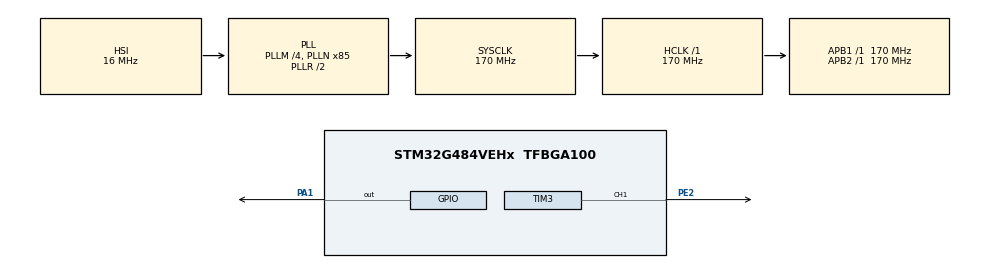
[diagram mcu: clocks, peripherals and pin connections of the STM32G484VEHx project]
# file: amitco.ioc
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Mcu.Family=STM32G4
Mcu.Name=STM32G484VEHx
Mcu.Package=TFBGA100
NVIC.PriorityGroup=NVIC_PRIORITYGROUP_4
PA1.Signal=GPIO_Output
PE2.Signal=S_TIM3_CH1
ProjectManager.HeapSize=0x200
ProjectManager.StackSize=0x400
ProjectManager.TargetToolchain=STM32CubeIDE
RCC.ADC12Freq_Value=170000000
RCC.ADC345Freq_Value=170000000
RCC.AHBFreq_Value=170000000
RCC.APB1Freq_Value=170000000
RCC.APB1TimFreq_Value=170000000
RCC.APB2Freq_Value=170000000
RCC.APB2TimFreq_Value=170000000
RCC.CortexFreq_Value=170000000
RCC.EXTERNAL_CLOCK_VALUE=12288000
RCC.HCLKFreq_Value=170000000
RCC.HSE_VALUE=8000000
RCC.HSI48_VALUE=48000000
RCC.HSI_VALUE=16000000
RCC.LSE_VALUE=32768
RCC.PLLM=RCC_PLLM_DIV4
RCC.PLLN=85
RCC.SYSCLKFreq_VALUE=170000000
RCC.SYSCLKSource=RCC_SYSCLKSOURCE_PLLCLK
RCC.USBFreq_Value=170000000
RCC.VCOOutputFreq_Value=340000000
SH.S_TIM3_CH1.0=TIM3_CH1,Output Compare1 CH1
TIM2.PeriodNoDither=9999
TIM2.Prescaler=169
TIM3.Channel-Output\ Compare1\ CH1=TIM_CHANNEL_1
TIM3.OCMode_1=TIM_OCMODE_TOGGLE
TIM3.PeriodNoDither=9999
TIM3.Prescaler=169
TIM3.PulseNoDither_1=5000
TIM3.TIM_MasterOutputTrigger=TIM_TRGO_OC1REF
VP_SYS_VS_DBSignals.Mode=DisableDeadBatterySignals
VP_TIM2_VS_ClockSourceINT.Mode=Internal
VP_TIM2_VS_ClockSourceITR.Mode=TriggerSource_ITR2
VP_TIM2_VS_ControllerModeReset.Mode=Reset Mode
VP_TIM3_VS_ClockSourceINT.Mode=Internal
board=custom

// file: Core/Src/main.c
/* USER CODE BEGIN Header */
/**
  ******************************************************************************
  * @file           : main.c
  * @brief          : Main program body
  ******************************************************************************
  * @attention
  *
  * Copyright (c) 2025 STMicroelectronics.
  * All rights reserved.
  *
  * This software is licensed under terms that can be found in the LICENSE file
  * in the root directory of this software component.
  * If no LICENSE file comes with this software, it is provided AS-IS.
  *
  ******************************************************************************
  */
/* USER CODE END Header */
#include "main.h"

TIM_HandleTypeDef htim2;
TIM_HandleTypeDef htim3;

/* USER CODE BEGIN PV */
volatile uint32_t tim2_cnt = 0;
volatile uint32_t tim3_cnt = 0;
/* USER CODE END PV */

void SystemClock_Config(void);
static void MX_GPIO_Init(void);
static void MX_TIM2_Init(void);
static void MX_TIM3_Init(void);

int main(void)
{

  /* MCU Configuration--------------------------------------------------------*/

  /* Reset of all peripherals, Initializes the Flash interface and the Systick. */
  HAL_Init();

  /* Configure the system clock */
  SystemClock_Config();

  /* Initialize all configured peripherals */
  MX_GPIO_Init();
  MX_TIM2_Init();
  MX_TIM3_Init();
  /* USER CODE BEGIN 2 */
  HAL_TIM_Base_Start(&htim2);
  HAL_TIM_Base_Start(&htim3);
  HAL_TIM_OC_Start(&htim3, TIM_CHANNEL_1);
  /* USER CODE END 2 */

  /* Infinite loop */
  while (1)
  {

    /* USER CODE BEGIN 3 */
  tim3_cnt = __HAL_TIM_GET_COUNTER(&htim3);
  tim2_cnt = __HAL_TIM_GET_COUNTER(&htim2);
  HAL_Delay(50);

  }
  /* USER CODE END 3 */
}

void SystemClock_Config(void)
{
  RCC_OscInitTypeDef RCC_OscInitStruct = {0};
  RCC_ClkInitTypeDef RCC_ClkInitStruct = {0};

  /** Configure the main internal regulator output voltage
  */
  HAL_PWREx_ControlVoltageScaling(PWR_REGULATOR_VOLTAGE_SCALE1_BOOST);

  /** Initializes the RCC Oscillators according to the specified parameters
  * in the RCC_OscInitTypeDef structure.
  */
  RCC_OscInitStruct.OscillatorType = RCC_OSCILLATORTYPE_HSI;
  RCC_OscInitStruct.HSIState = RCC_HSI_ON;
  RCC_OscInitStruct.HSICalibrationValue = RCC_HSICALIBRATION_DEFAULT;
  RCC_OscInitStruct.PLL.PLLState = RCC_PLL_ON;
  RCC_OscInitStruct.PLL.PLLSource = RCC_PLLSOURCE_HSI;
  RCC_OscInitStruct.PLL.PLLM = RCC_PLLM_DIV4;
  RCC_OscInitStruct.PLL.PLLN = 85;
  RCC_OscInitStruct.PLL.PLLP = RCC_PLLP_DIV2;
  RCC_OscInitStruct.PLL.PLLQ = RCC_PLLQ_DIV2;
  RCC_OscInitStruct.PLL.PLLR = RCC_PLLR_DIV2;
  if (HAL_RCC_OscConfig(&RCC_OscInitStruct) != HAL_OK)
  {
    Error_Handler();
  }

  /** Initializes the CPU, AHB and APB buses clocks
  */
  RCC_ClkInitStruct.ClockType = RCC_CLOCKTYPE_HCLK|RCC_CLOCKTYPE_SYSCLK
                              |RCC_CLOCKTYPE_PCLK1|RCC_CLOCKTYPE_PCLK2;
  RCC_ClkInitStruct.SYSCLKSource = RCC_SYSCLKSOURCE_PLLCLK;
  RCC_ClkInitStruct.AHBCLKDivider = RCC_SYSCLK_DIV1;
  RCC_ClkInitStruct.APB1CLKDivider = RCC_HCLK_DIV1;
  RCC_ClkInitStruct.APB2CLKDivider = RCC_HCLK_DIV1;

  if (HAL_RCC_ClockConfig(&RCC_ClkInitStruct, FLASH_LATENCY_4) != HAL_OK)
  {
    Error_Handler();
  }
}

static void MX_TIM2_Init(void)
{

  TIM_ClockConfigTypeDef sClockSourceConfig = {0};
  TIM_SlaveConfigTypeDef sSlaveConfig = {0};
  TIM_MasterConfigTypeDef sMasterConfig = {0};

  htim2.Instance = TIM2;
  htim2.Init.Prescaler = 169;
  htim2.Init.CounterMode = TIM_COUNTERMODE_UP;
  htim2.Init.Period = 9999;
  htim2.Init.ClockDivision = TIM_CLOCKDIVISION_DIV1;
  htim2.Init.AutoReloadPreload = TIM_AUTORELOAD_PRELOAD_DISABLE;
  if (HAL_TIM_Base_Init(&htim2) != HAL_OK)
  {
    Error_Handler();
  }
  sClockSourceConfig.ClockSource = TIM_CLOCKSOURCE_INTERNAL;
  if (HAL_TIM_ConfigClockSource(&htim2, &sClockSourceConfig) != HAL_OK)
  {
    Error_Handler();
  }
  sSlaveConfig.SlaveMode = TIM_SLAVEMODE_RESET;
  sSlaveConfig.InputTrigger = TIM_TS_ITR2;
  if (HAL_TIM_SlaveConfigSynchro(&htim2, &sSlaveConfig) != HAL_OK)
  {
    Error_Handler();
  }
  sMasterConfig.MasterOutputTrigger = TIM_TRGO_RESET;
  sMasterConfig.MasterSlaveMode = TIM_MASTERSLAVEMODE_DISABLE;
  if (HAL_TIMEx_MasterConfigSynchronization(&htim2, &sMasterConfig) != HAL_OK)
  {
    Error_Handler();
  }

}

static void MX_TIM3_Init(void)
{

  TIM_ClockConfigTypeDef sClockSourceConfig = {0};
  TIM_MasterConfigTypeDef sMasterConfig = {0};
  TIM_OC_InitTypeDef sConfigOC = {0};

  htim3.Instance = TIM3;
  htim3.Init.Prescaler = 169;
  htim3.Init.CounterMode = TIM_COUNTERMODE_UP;
  htim3.Init.Period = 9999;
  htim3.Init.ClockDivision = TIM_CLOCKDIVISION_DIV1;
  htim3.Init.AutoReloadPreload = TIM_AUTORELOAD_PRELOAD_DISABLE;
  if (HAL_TIM_Base_Init(&htim3) != HAL_OK)
  {
    Error_Handler();
  }
  sClockSourceConfig.ClockSource = TIM_CLOCKSOURCE_INTERNAL;
  if (HAL_TIM_ConfigClockSource(&htim3, &sClockSourceConfig) != HAL_OK)
  {
    Error_Handler();
  }
  if (HAL_TIM_OC_Init(&htim3) != HAL_OK)
  {
    Error_Handler();
  }
  sMasterConfig.MasterOutputTrigger = TIM_TRGO_OC1REF;
  sMasterConfig.MasterSlaveMode = TIM_MASTERSLAVEMODE_DISABLE;
  if (HAL_TIMEx_MasterConfigSynchronization(&htim3, &sMasterConfig) != HAL_OK)
  {
    Error_Handler();
  }
  sConfigOC.OCMode = TIM_OCMODE_TOGGLE;
  sConfigOC.Pulse = 5000;
  sConfigOC.OCPolarity = TIM_OCPOLARITY_HIGH;
  sConfigOC.OCFastMode = TIM_OCFAST_DISABLE;
  if (HAL_TIM_OC_ConfigChannel(&htim3, &sConfigOC, TIM_CHANNEL_1) != HAL_OK)
  {
    Error_Handler();
  }
  HAL_TIM_MspPostInit(&htim3);

}

static void MX_GPIO_Init(void)
{
  GPIO_InitTypeDef GPIO_InitStruct = {0};

  /* GPIO Ports Clock Enable */
  __HAL_RCC_GPIOE_CLK_ENABLE();
  __HAL_RCC_GPIOA_CLK_ENABLE();

  /*Configure GPIO pin Output Level */
  HAL_GPIO_WritePin(GPIOA, GPIO_PIN_1, GPIO_PIN_RESET);

  /*Configure GPIO pin : PA1 */
  GPIO_InitStruct.Pin = GPIO_PIN_1;
  GPIO_InitStruct.Mode = GPIO_MODE_OUTPUT_PP;
  GPIO_InitStruct.Pull = GPIO_NOPULL;
  GPIO_InitStruct.Speed = GPIO_SPEED_FREQ_LOW;
  HAL_GPIO_Init(GPIOA, &GPIO_InitStruct);

}

void Error_Handler(void)
{
  __disable_irq();
  while (1)
  {
  }
}
